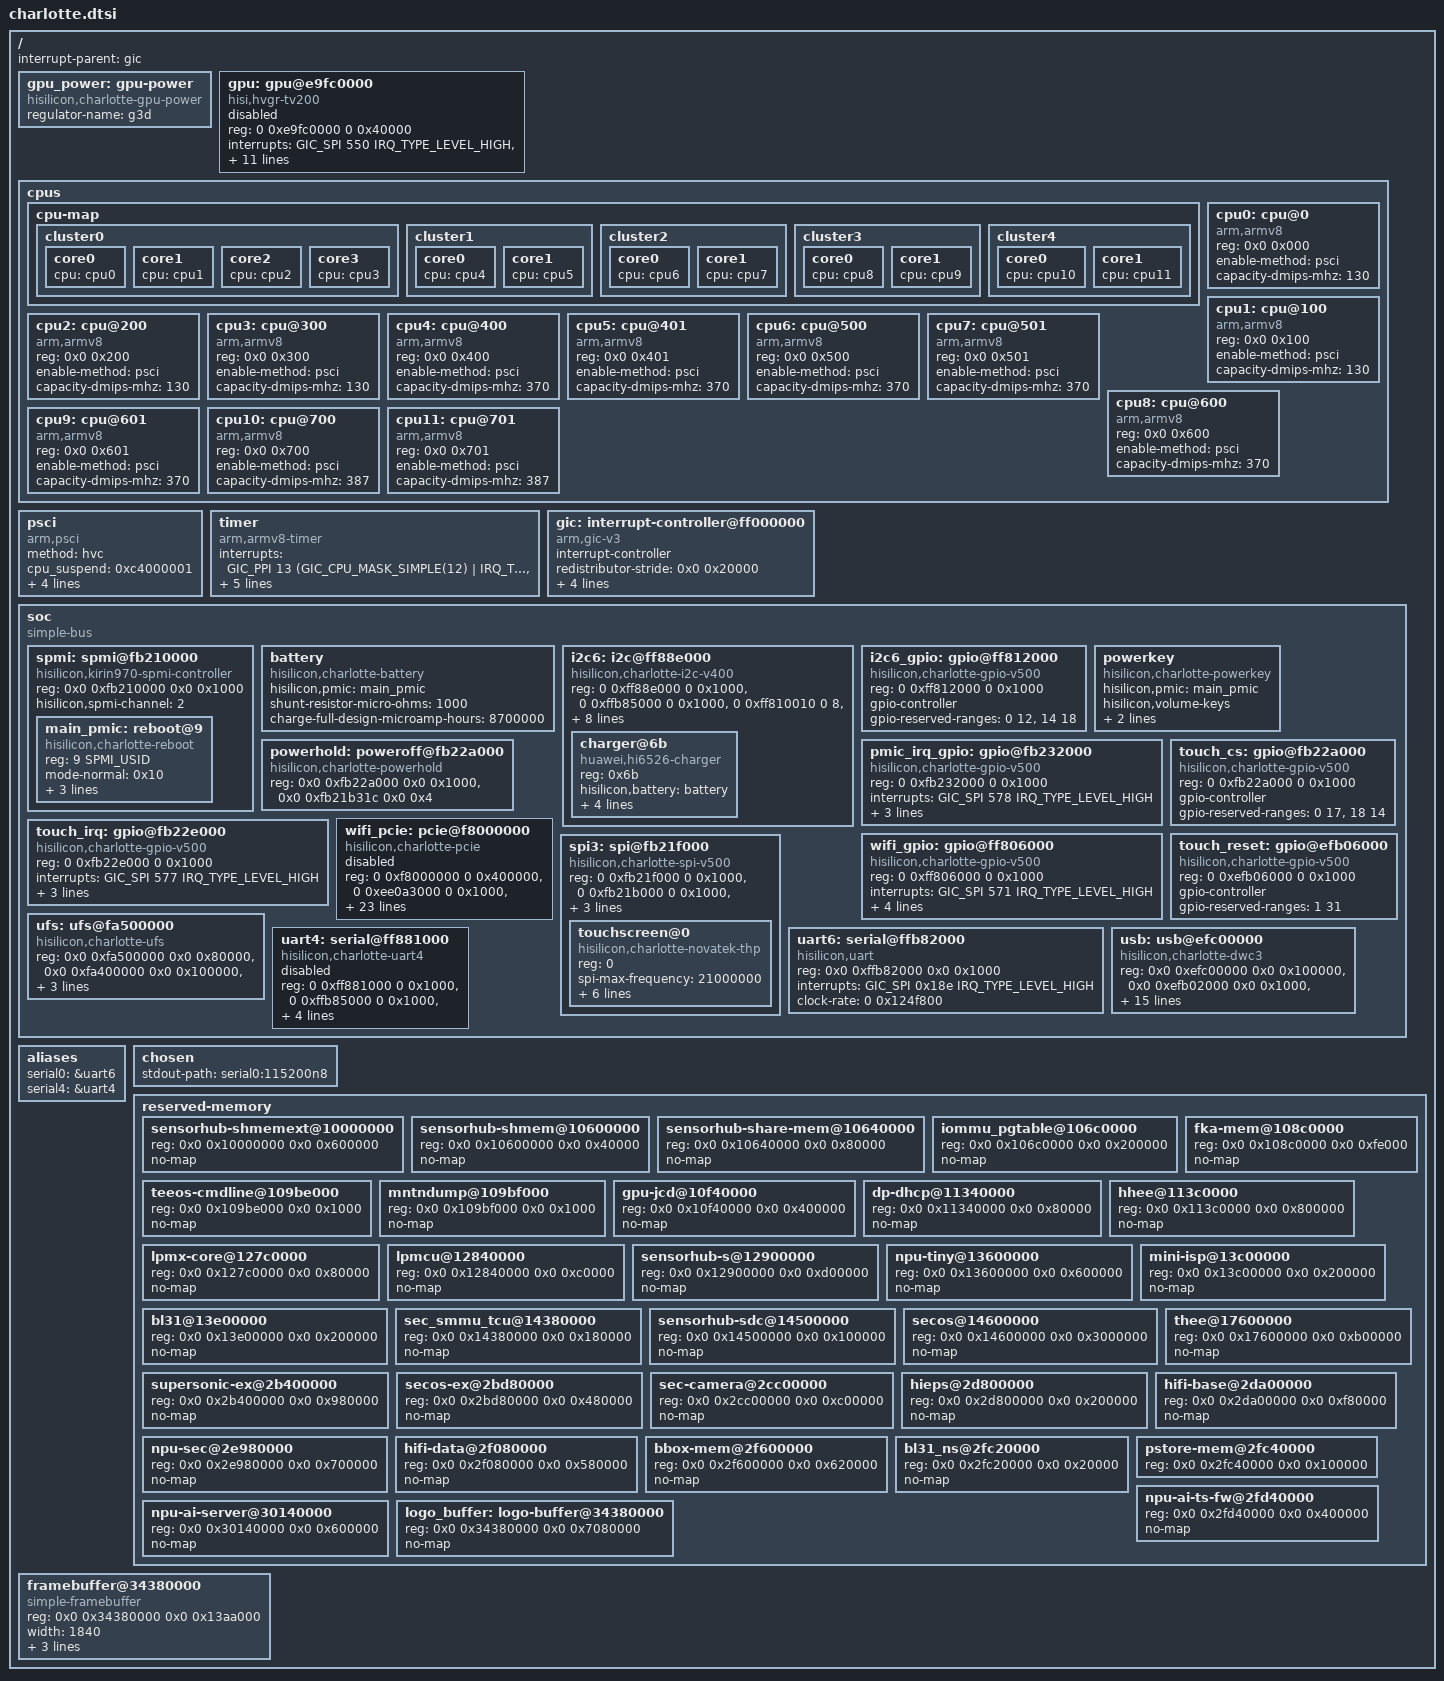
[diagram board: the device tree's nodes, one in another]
// SPDX-License-Identifier: GPL-2.0
/*
 * Hisilicon kirin9000s (charlotte) SoC core support
 *
 */

#include <dt-bindings/interrupt-controller/arm-gic.h>
#include <dt-bindings/spmi/spmi.h>
#include <dt-bindings/gpio/gpio.h>
/ {
	interrupt-parent = <&gic>;

	#address-cells = <2>;
	#size-cells = <2>;

	gpu_power: gpu-power {
		compatible = "hisilicon,charlotte-gpu-power";
		regulator-name = "g3d";
	};

	/* Stock TGR uses HiSilicon HVGR TV200, with six separate IRQ lines.
	 * Power is an IP vote to the platform FF-A partition, not a fixed rail.
	 * The vendor system-cache extension is disabled during initial bring-up.
	 */
	gpu: gpu@e9fc0000 {
		compatible = "hisi,hvgr-tv200", "hisi,hvgr";
		reg = <0 0xe9fc0000 0 0x40000>;
		interrupts = <GIC_SPI 550 IRQ_TYPE_LEVEL_HIGH>,
			     <GIC_SPI 551 IRQ_TYPE_LEVEL_HIGH>,
			     <GIC_SPI 552 IRQ_TYPE_LEVEL_HIGH>,
			     <GIC_SPI 553 IRQ_TYPE_LEVEL_HIGH>,
			     <GIC_SPI 627 IRQ_TYPE_LEVEL_HIGH>,
			     <GIC_SPI 628 IRQ_TYPE_LEVEL_HIGH>;
		interrupt-names = "FCP", "GPU", "JOB", "MMU", "CQ", "CC";
		gpu-supply = <&gpu_power>;
		system-coherency = <31>;
		crg-reset = <0xffb85000 0x1000 0xd18 0x07800000
			     0xd1c 0x07800000>;
		prot_enhance = <0>;
		protect_space = <0x10f40000 0x400000>;
		status = "disabled";
	};

	cpus {
		#address-cells = <2>;
		#size-cells = <0>;

		cpu-map {
			cluster0 {
				core0 { cpu = <&cpu0>; };
				core1 { cpu = <&cpu1>; };
				core2 { cpu = <&cpu2>; };
				core3 { cpu = <&cpu3>; };
			};
			cluster1 {
				core0 { cpu = <&cpu4>; };
				core1 { cpu = <&cpu5>; };
			};
			cluster2 {
				core0 { cpu = <&cpu6>; };
				core1 { cpu = <&cpu7>; };
			};
			cluster3 {
				core0 { cpu = <&cpu8>; };
				core1 { cpu = <&cpu9>; };
			};
			cluster4 {
				core0 { cpu = <&cpu10>; };
				core1 { cpu = <&cpu11>; };
			};
		};

		cpu0: cpu@0 {
			device_type = "cpu";
			compatible = "arm,armv8";
			reg = <0x0 0x000>;
			enable-method = "psci";
			capacity-dmips-mhz = <130>;
		};
		cpu1: cpu@100 {
			device_type = "cpu";
			compatible = "arm,armv8";
			reg = <0x0 0x100>;
			enable-method = "psci";
			capacity-dmips-mhz = <130>;
		};
		cpu2: cpu@200 {
			device_type = "cpu";
			compatible = "arm,armv8";
			reg = <0x0 0x200>;
			enable-method = "psci";
			capacity-dmips-mhz = <130>;
		};
		cpu3: cpu@300 {
			device_type = "cpu";
			compatible = "arm,armv8";
			reg = <0x0 0x300>;
			enable-method = "psci";
			capacity-dmips-mhz = <130>;
		};
		/* Taishan CPUs use the Charlotte firmware handoff in arm64 SMP. */
		cpu4: cpu@400 {
			device_type = "cpu";
			compatible = "arm,armv8";
			reg = <0x0 0x400>;
			enable-method = "psci";
			capacity-dmips-mhz = <370>;
			status = "okay";
		};
		cpu5: cpu@401 {
			device_type = "cpu";
			compatible = "arm,armv8";
			reg = <0x0 0x401>;
			enable-method = "psci";
			capacity-dmips-mhz = <370>;
			status = "okay";
		};
		cpu6: cpu@500 {
			device_type = "cpu";
			compatible = "arm,armv8";
			reg = <0x0 0x500>;
			enable-method = "psci";
			capacity-dmips-mhz = <370>;
			status = "okay";
		};
		cpu7: cpu@501 {
			device_type = "cpu";
			compatible = "arm,armv8";
			reg = <0x0 0x501>;
			enable-method = "psci";
			capacity-dmips-mhz = <370>;
			status = "okay";
		};
		cpu8: cpu@600 {
			device_type = "cpu";
			compatible = "arm,armv8";
			reg = <0x0 0x600>;
			enable-method = "psci";
			capacity-dmips-mhz = <370>;
			status = "okay";
		};
		cpu9: cpu@601 {
			device_type = "cpu";
			compatible = "arm,armv8";
			reg = <0x0 0x601>;
			enable-method = "psci";
			capacity-dmips-mhz = <370>;
			status = "okay";
		};
		cpu10: cpu@700 {
			device_type = "cpu";
			compatible = "arm,armv8";
			reg = <0x0 0x700>;
			enable-method = "psci";
			capacity-dmips-mhz = <387>;
			status = "okay";
		};
		cpu11: cpu@701 {
			device_type = "cpu";
			compatible = "arm,armv8";
			reg = <0x0 0x701>;
			enable-method = "psci";
			capacity-dmips-mhz = <387>;
			status = "okay";
		};
	};

	psci {
		compatible = "arm,psci";
		method = "hvc";
		cpu_suspend = <0xc4000001>;
		cpu_off   = <0x84000002>;
		cpu_on    = <0xc4000003>;
		system_off = <0x84000008>;
		system_reset = <0x84000009>;
	};

	timer {
		compatible = "arm,armv8-timer";
		interrupts = <GIC_PPI 13 (GIC_CPU_MASK_SIMPLE(12) | IRQ_TYPE_LEVEL_LOW)>,
			     <GIC_PPI 14 (GIC_CPU_MASK_SIMPLE(12) | IRQ_TYPE_LEVEL_LOW)>,
			     <GIC_PPI 11 (GIC_CPU_MASK_SIMPLE(12) | IRQ_TYPE_LEVEL_LOW)>,
			     <GIC_PPI 10 (GIC_CPU_MASK_SIMPLE(12) | IRQ_TYPE_LEVEL_LOW)>;
		clock-frequency = <1920000>;
		arm,no-tick-in-suspend;
	};

	gic: interrupt-controller@ff000000 {
		compatible = "arm,gic-v3";
		#interrupt-cells = <3>;
		#address-cells = <2>;
		#size-cells = <2>;
		ranges;
		interrupt-controller;
		redistributor-stride = <0x0 0x20000>;
		#redistributor-regions = <1>;
		reg = <0x0 0xff000000 0x0 0x10000>,
		      <0x0 0xff040000 0x0 0x180000>;
		interrupts = <GIC_PPI 9 IRQ_TYPE_LEVEL_HIGH>;
	};

	soc: soc {
		compatible = "simple-bus";
		#address-cells = <2>;
		#size-cells = <2>;
		ranges;

		spmi: spmi@fb210000 {
			/* Same command/register layout as the upstream Kirin970 driver. */
			compatible = "hisilicon,kirin970-spmi-controller";
			reg = <0x0 0xfb210000 0x0 0x1000>;
			hisilicon,spmi-channel = <2>;
			#address-cells = <2>;
			#size-cells = <0>;

			main_pmic: reboot@9 {
				compatible = "hisilicon,charlotte-reboot";
				reg = <9 SPMI_USID>;
				mode-normal = <0x10>;
				mode-bootloader = <0x01>;
				hisilicon,watchdog-recovery-bootloader;
				hisilicon,powerhold = <&powerhold>;
			};
		};

		battery: battery {
			compatible = "hisilicon,charlotte-battery";
			hisilicon,pmic = <&main_pmic>;
			shunt-resistor-micro-ohms = <1000>;
			charge-full-design-microamp-hours = <8700000>;
		};

		i2c6: i2c@ff88e000 {
			compatible = "hisilicon,charlotte-i2c-v400";
			reg = <0 0xff88e000 0 0x1000>,
			      <0 0xffb85000 0 0x1000>,
			      <0 0xff810010 0 8>,
			      <0 0xff811810 0 8>,
			      <0 0xff811010 0 8>;
			reg-names = "controller", "crg", "iomux", "pad", "function";
			interrupts = <GIC_SPI 359 IRQ_TYPE_LEVEL_HIGH>;
			clk_rate = <0 112000000>;
			clock-frequency = <100000>;
			i2c-sda-hold-time-ns = <554>;
			i2c-digital-filter-width-ns = <9>;
			scl-gpios = <&i2c6_gpio 12 (GPIO_ACTIVE_HIGH | GPIO_OPEN_DRAIN)>;
			sda-gpios = <&i2c6_gpio 13 (GPIO_ACTIVE_HIGH | GPIO_OPEN_DRAIN)>;
			#address-cells = <1>;
			#size-cells = <0>;

			charger@6b {
				compatible = "huawei,hi6526-charger";
				reg = <0x6b>;
				hisilicon,battery = <&battery>;
				hisilicon,usb-controller = <&usb>;
				irq-gpios = <&touch_irq 15 GPIO_ACTIVE_LOW>;
				interrupt-parent = <&touch_irq>;
				interrupts = <15 IRQ_TYPE_LEVEL_LOW>;
			};
		};

		i2c6_gpio: gpio@ff812000 {
			compatible = "hisilicon,charlotte-gpio-v500";
			reg = <0 0xff812000 0 0x1000>;
			gpio-controller;
			#gpio-cells = <2>;
			gpio-reserved-ranges = <0 12>, <14 18>;
		};

		powerkey {
			compatible = "hisilicon,charlotte-powerkey";
			hisilicon,pmic = <&main_pmic>;
			hisilicon,volume-keys;
			interrupt-parent = <&pmic_irq_gpio>;
			interrupts = <13 IRQ_TYPE_LEVEL_LOW>;
		};

		/* Stock PMIC interrupt is GPIO237: bank 7 offset 13. */
		pmic_irq_gpio: gpio@fb232000 {
			compatible = "hisilicon,charlotte-gpio-v500";
			reg = <0 0xfb232000 0 0x1000>;
			interrupts = <GIC_SPI 578 IRQ_TYPE_LEVEL_HIGH>;
			gpio-controller;
			#gpio-cells = <2>;
			interrupt-controller;
			#interrupt-cells = <2>;
			#address-cells = <0>;
			gpio-reserved-ranges = <0 13>, <14 1>, <17 15>;
		};

		powerhold: poweroff@fb22a000 {
			compatible = "hisilicon,charlotte-powerhold";
			/* Vendor GPIO176 = GPIO bank 5 offset 16; SCTRL protect bit 15. */
			reg = <0x0 0xfb22a000 0x0 0x1000>,
			      <0x0 0xfb21b31c 0x0 0x4>;
			reg-names = "gpio", "protect";
		};

		/* Expose CS177, charger IRQ207, touch IRQ222 and reset352; other lines
		 * remain owned by firmware (including powerhold GPIO176).
		 */
		touch_cs: gpio@fb22a000 {
			compatible = "hisilicon,charlotte-gpio-v500";
			reg = <0 0xfb22a000 0 0x1000>;
			gpio-controller;
			#gpio-cells = <2>;
			gpio-reserved-ranges = <0 17>, <18 14>;
		};

		touch_irq: gpio@fb22e000 {
			compatible = "hisilicon,charlotte-gpio-v500";
			reg = <0 0xfb22e000 0 0x1000>;
			interrupts = <GIC_SPI 577 IRQ_TYPE_LEVEL_HIGH>;
			gpio-controller;
			#gpio-cells = <2>;
			interrupt-controller;
			#interrupt-cells = <2>;
			#address-cells = <0>;
			gpio-reserved-ranges = <0 13>, <16 14>, <31 1>;
		};

		/* Stock Hi1105 chip power and TCXO frequency strap. */
		wifi_gpio: gpio@ff806000 {
			compatible = "hisilicon,charlotte-gpio-v500";
			reg = <0 0xff806000 0 0x1000>;
			interrupts = <GIC_SPI 571 IRQ_TYPE_LEVEL_HIGH>;
			gpio-controller;
			#gpio-cells = <2>;
			interrupt-controller;
			#interrupt-cells = <2>;
			#address-cells = <0>;
			gpio-reserved-ranges = <0 5>, <6 1>, <9 1>, <11 3>, <16 16>;
		};

		wifi_pcie: pcie@f8000000 {
			compatible = "hisilicon,charlotte-pcie";
			device_type = "pci";
			#address-cells = <3>;
			#size-cells = <2>;
			#interrupt-cells = <1>;
			reg = <0 0xf8000000 0 0x400000>,
			      <0 0xee0a3000 0 0x1000>,
			      <0 0xee0a0000 0 0x3000>,
			      <0 0xf8400000 0 0x2000>,
			      <0 0xee262000 0 0x1000>,
			      <0 0xffb81000 0 0x1000>,
			      <0 0xee263000 0 0x1000>,
			      <0 0xefb02000 0 0x1000>;
			reg-names = "dbi", "apb", "phy", "config", "hsdt-crg",
				    "pmctrl", "fnpll", "aux-crg";
			phy_layout_info = <0 0 0x2000>;
			ranges = <0x02000000 0 0xf8500000 0 0xf8500000 0 0x01d00000>;
			bus-range = <0 0xff>;
			num-lanes = <1>;
			max-link-speed = <2>;
			interrupts = <GIC_SPI 92 IRQ_TYPE_EDGE_RISING>;
			interrupt-names = "linkdown";
			interrupt-map-mask = <0 0 0 7>;
			interrupt-map = <0 0 0 1 &gic 0 0 GIC_SPI 93 IRQ_TYPE_LEVEL_HIGH>,
					<0 0 0 2 &gic 0 0 GIC_SPI 94 IRQ_TYPE_LEVEL_HIGH>,
					<0 0 0 3 &gic 0 0 GIC_SPI 95 IRQ_TYPE_LEVEL_HIGH>,
					<0 0 0 4 &gic 0 0 GIC_SPI 96 IRQ_TYPE_LEVEL_HIGH>;
			chip-power-gpios = <&wifi_gpio 15 GPIO_ACTIVE_HIGH>;
			wlan-power-gpios = <&touch_irq 14 GPIO_ACTIVE_HIGH>;
			tcxo-gpios = <&wifi_gpio 10 GPIO_ACTIVE_HIGH>;
			hisilicon,pmic = <&main_pmic>;
			/* Bring-up only until the transport owns the GPIO/clock lifecycle. */
			status = "disabled";
		};

		touch_reset: gpio@efb06000 {
			compatible = "hisilicon,charlotte-gpio-v500";
			reg = <0 0xefb06000 0 0x1000>;
			gpio-controller;
			#gpio-cells = <2>;
			gpio-reserved-ranges = <1 31>;
		};

		spi3: spi@fb21f000 {
			compatible = "hisilicon,charlotte-spi-v500";
			reg = <0 0xfb21f000 0 0x1000>,
			      <0 0xfb21b000 0 0x1000>,
			      <0 0xfb228000 0 0x1000>,
			      <0 0xfb229000 0 0x1000>,
			      <0 0xefb04000 0 0x1000>;
			#address-cells = <1>;
			#size-cells = <0>;
			cs-gpios = <&touch_cs 17 GPIO_ACTIVE_LOW>;

			touchscreen@0 {
				compatible = "hisilicon,charlotte-novatek-thp";
				reg = <0>;
				spi-max-frequency = <21000000>;
				spi-cs-setup-delay-ns = <200>;
				spi-cs-inactive-delay-ns = <1000>;
				reset-gpios = <&touch_reset 0 GPIO_ACTIVE_LOW>;
				irq-gpios = <&touch_irq 30 GPIO_ACTIVE_HIGH>;
				interrupt-parent = <&touch_irq>;
				interrupts = <30 IRQ_TYPE_EDGE_FALLING>;
			};
		};

		ufs: ufs@fa500000 {
			compatible = "hisilicon,charlotte-ufs";
			reg = <0x0 0xfa500000 0x0 0x80000>,
			      <0x0 0xfa400000 0x0 0x100000>,
			      <0x0 0xfa3fd000 0x0 0x1000>,
			      <0x0 0xfa58a000 0x0 0x1000>;
			reg-names = "hci", "unipro", "crg", "mphy-mcu";
			interrupts = <GIC_SPI 134 IRQ_TYPE_LEVEL_HIGH>;
		};

		uart4: serial@ff881000 {
			compatible = "hisilicon,charlotte-uart4", "hisilicon,uart";
			reg = <0 0xff881000 0 0x1000>,
			      <0 0xffb85000 0 0x1000>,
			      <0 0xff800000 0 0x1000>,
			      <0 0xff801000 0 0x1000>;
			reg-names = "uart", "peri-crg", "mux", "pads";
			interrupts = <GIC_SPI 396 IRQ_TYPE_LEVEL_HIGH>;
			/* SPLL / 5 / 2, as rounded by the vendor clock driver. */
			clock-rate = <0 167116800>;
			hisilicon,cts-active-low;
			status = "disabled";
		};

		uart6: serial@ffb82000 {
			compatible = "hisilicon,uart";
			reg = <0x0 0xffb82000 0x0 0x1000>;
			interrupts = <GIC_SPI 0x18e IRQ_TYPE_LEVEL_HIGH>;
			clock-rate = <0 0x124f800>;	/* 19.2 MHz */
			status = "okay";
		};

		usb: usb@efc00000 {
			compatible = "hisilicon,charlotte-dwc3";
			reg = <0x0 0xefc00000 0x0 0x100000>,
			      <0x0 0xefb02000 0x0 0x1000>,
			      <0x0 0xffb85000 0x0 0x1000>,
			      <0x0 0xffb81000 0x0 0x1000>,
			      <0x0 0xfb21b000 0x0 0x1000>,
			      <0x0 0xefa02000 0x0 0x1000>,
			      <0x0 0xfb913000 0x0 0x1000>,
			      <0x0 0xefab0000 0x0 0x1000>;
			reg-names = "dwc3", "hsdt-crg", "peri-crg", "pmctrl",
				    "sysctrl", "misc", "sysqic", "utmi";
			interrupts = <GIC_SPI 140 IRQ_TYPE_LEVEL_HIGH>;
			interrupt-names = "peripheral";
			dr_mode = "peripheral";
			maximum-speed = "high-speed";
			snps,hsphy_interface = "utmi";
			snps,dis_u2_susphy_quirk;
			snps,dis_u3_susphy_quirk;
			snps,dis_enblslpm_quirk;
			snps,dis-split-quirk;
			snps,gctl-reset-quirk;
		};
	};

	aliases {
		serial0 = &uart6;
		serial4 = &uart4;
	};

	chosen {
		stdout-path = "serial0:115200n8";
	};

	reserved-memory {
		#address-cells = <2>;
		#size-cells = <2>;
		ranges;
		/*
		 * Fixed reservations from the live UEFI FDT. Preserve every
		 * enabled firmware region: an absent Linux driver does not
		 * establish that EL3 has released its DDR protection. Reusable
		 * Linux CMA pools and disabled loader areas are not copied.
		 */
		sensorhub-shmemext@10000000 {
			reg = <0x0 0x10000000 0x0 0x600000>;
			no-map;
		};

		sensorhub-shmem@10600000 {
			reg = <0x0 0x10600000 0x0 0x40000>;
			no-map;
		};

		sensorhub-share-mem@10640000 {
			reg = <0x0 0x10640000 0x0 0x80000>;
			no-map;
		};

		/* Bootloader display-SMMU page tables: live while the DPU
		 * keeps scanning out the logo. */
		iommu_pgtable@106c0000 {
			reg = <0x0 0x106c0000 0x0 0x200000>;
			no-map;
		};

		/* Firmware scratch pool (stock ddr_inspect); the FF-A RXTX
		 * buffers live here (Android ffa: RX 0x10967000, TX 0x10968000).
		 * no-map so the FF-A driver can ioremap_wc them with no
		 * linear alias. */
		fka-mem@108c0000 {
			reg = <0x0 0x108c0000 0x0 0xfe000>;
			no-map;
		};

		/* TEE OS command-line page. */
		teeos-cmdline@109be000 {
			reg = <0x0 0x109be000 0x0 0x1000>;
			no-map;
		};

		/* Firmware mntn black-box dump magic page. */
		mntndump@109bf000 {
			reg = <0x0 0x109bf000 0x0 0x1000>;
			no-map;
		};

		/* The v172 /init source page was in this GPU protected range. */
		gpu-jcd@10f40000 {
			reg = <0x0 0x10f40000 0x0 0x400000>;
			no-map;
		};

		/* Firmware DP/display shared buffer between gpu-jcd and hhee. */
		dp-dhcp@11340000 {
			reg = <0x0 0x11340000 0x0 0x80000>;
			no-map;
		};

		/* EL2 monitor (hhee) memory. */
		hhee@113c0000 {
			reg = <0x0 0x113c0000 0x0 0x800000>;
			no-map;
		};

		/* LPM3 always-on island (warm reset / watchdog owner). */
		lpmx-core@127c0000 {
			reg = <0x0 0x127c0000 0x0 0x80000>;
			no-map;
		};

		lpmcu@12840000 {
			reg = <0x0 0x12840000 0x0 0xc0000>;
			no-map;
		};

		sensorhub-s@12900000 {
			reg = <0x0 0x12900000 0x0 0xd00000>;
			no-map;
		};

		npu-tiny@13600000 {
			reg = <0x0 0x13600000 0x0 0x600000>;
			no-map;
		};

		mini-isp@13c00000 {
			reg = <0x0 0x13c00000 0x0 0x200000>;
			no-map;
		};

		/* ARM Trusted Firmware EL3 runtime (PSCI/FF-A conduit). */
		bl31@13e00000 {
			reg = <0x0 0x13e00000 0x0 0x200000>;
			no-map;
		};

		/* Secure SMMU TCU page tables (GPU protect stream). */
		sec_smmu_tcu@14380000 {
			reg = <0x0 0x14380000 0x0 0x180000>;
			no-map;
		};

		sensorhub-sdc@14500000 {
			reg = <0x0 0x14500000 0x0 0x100000>;
			no-map;
		};

		/* Secure OS (TrustZone) image and data. */
		secos@14600000 {
			reg = <0x0 0x14600000 0x0 0x3000000>;
			no-map;
		};

		thee@17600000 {
			reg = <0x0 0x17600000 0x0 0xb00000>;
			no-map;
		};

		/* TEE-protected memory (stock platform-supersonic-ex). */
		supersonic-ex@2b400000 {
			reg = <0x0 0x2b400000 0x0 0x980000>;
			no-map;
		};

		/* Secure OS extension (stock platform-secos-ex). */
		secos-ex@2bd80000 {
			reg = <0x0 0x2bd80000 0x0 0x480000>;
			no-map;
		};

		sec-camera@2cc00000 {
			reg = <0x0 0x2cc00000 0x0 0xc00000>;
			no-map;
		};

		hieps@2d800000 {
			reg = <0x0 0x2d800000 0x0 0x200000>;
			no-map;
		};

		hifi-base@2da00000 {
			reg = <0x0 0x2da00000 0x0 0xf80000>;
			no-map;
		};

		npu-sec@2e980000 {
			reg = <0x0 0x2e980000 0x0 0x700000>;
			no-map;
		};

		hifi-data@2f080000 {
			reg = <0x0 0x2f080000 0x0 0x580000>;
			no-map;
		};

		bbox-mem@2f600000 {
			reg = <0x0 0x2f600000 0x0 0x620000>;
			no-map;
		};

		/* BL31 non-secure shared buffer (SMC payload/log). */
		bl31_ns@2fc20000 {
			reg = <0x0 0x2fc20000 0x0 0x20000>;
			no-map;
		};

		/* Ramoops: keep mapped so the console log stays readable. */
		pstore-mem@2fc40000 {
			reg = <0x0 0x2fc40000 0x0 0x100000>;
		};

		npu-ai-ts-fw@2fd40000 {
			reg = <0x0 0x2fd40000 0x0 0x400000>;
			no-map;
		};

		npu-ai-server@30140000 {
			reg = <0x0 0x30140000 0x0 0x600000>;
			no-map;
		};

		/*
		 * UEFI logo framebuffer: HwLogoDxe reads
		 * /reserved-memory/logo-buffer and the DPU scans out this
		 * physical address while Linux boots (no ExitBootServices
		 * teardown in the display DXE drivers).  Reserve it so the
		 * kernel never hands these pages out.
		 */
		logo_buffer: logo-buffer@34380000 {
			reg = <0x0 0x34380000 0x0 0x7080000>;
			no-map;
		};
	};

	/*
	 * Handoff framebuffer: the DPU is left scanning the logo buffer.
	 * Geometry measured from the vendor kernel's own fb0 (read-only
	 * FBIOGET ioctls): 1840x2800, 32 bpp, stride 7360, memory order
	 * B,G,R,X (red 16:8, green 8:8, blue 0:8 -> "x8b8g8r8").  The old
	 * 2800x1840/11200 guess produced the v49 horizontal tearing.
	 */
	framebuffer@34380000 {
		compatible = "simple-framebuffer";
		reg = <0x0 0x34380000 0x0 0x13aa000>;
		width = <1840>;
		height = <2800>;
		stride = <7360>;
		format = "x8b8g8r8";
	};
};
